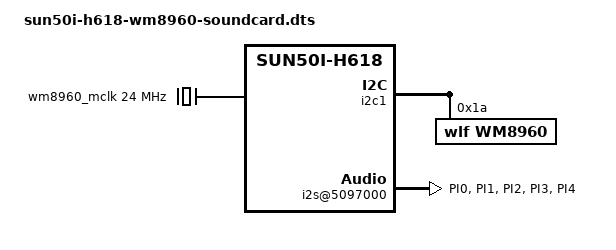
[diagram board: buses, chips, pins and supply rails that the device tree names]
/*
 * Device Tree Overlay for WM8960 Audio Codec (ReSpeaker 2-Mic HAT / Keyestudio)
 * on Orange Pi Zero 2W (Allwinner H618)
 *
 * Copyright (C) 2025
 * License: MIT
 *
 * This overlay enables the WM8960 codec connected via:
 *   - I2C for control (address 0x1a on /dev/i2c-3)
 *   - I2S for audio data via AHUB I2S2
 *
 * IMPORTANT: This overlay requires the base i2c1-pi overlay to be enabled first!
 *   In /boot/armbianEnv.txt, ensure:
 *     overlays=i2c1-pi sun50i-h618-wm8960-soundcard
 *
 * GPIO Pin Mapping (40-pin header):
 *   Pin 3  (PI8)  - I2C SDA 
 *   Pin 5  (PI7)  - I2C SCL
 *   Pin 12 (PI1)  - I2S BCLK
 *   Pin 35 (PI2)  - I2S LRCK
 *   Pin 38 (PI4)  - I2S DIN
 *   Pin 40 (PI3)  - I2S DOUT
 *
 * After enabling i2c1-pi overlay, the I2C appears as /dev/i2c-3
 * The WM8960 should be detected at address 0x1a on that bus.
 */

/dts-v1/;
/plugin/;

/ {
	compatible = "xunlong,orangepi-zero2w", "allwinner,sun50i-h618";

	/* Fragment 0: Add WM8960 codec to I2C1 (which becomes /dev/i2c-3 with i2c1-pi overlay) */
	fragment@0 {
		target = <&i2c1>;
		__overlay__ {
			#address-cells = <1>;
			#size-cells = <0>;
			status = "okay";

			wm8960: wm8960@1a {
				compatible = "wlf,wm8960";
				reg = <0x1a>;
				#sound-dai-cells = <0>;
				wlf,shared-lrclk;
			};
		};
	};

	/* Fragment 1: Define I2S2 pins for audio */
	fragment@1 {
		target = <&pio>;
		__overlay__ {
			i2s2_wm8960_pins: i2s2-wm8960-pins {
				pins = "PI0", "PI1", "PI2", "PI3", "PI4";
				function = "i2s2";
			};
		};
	};

	/* Fragment 2: Enable I2S2 interface with external pinctrl */
	fragment@2 {
		target-path = "/soc/i2s@5097000";
		__overlay__ {
			status = "okay";
			pinctrl-names = "default";
			pinctrl-0 = <&i2s2_wm8960_pins>;
		};
	};

	/* Fragment 3: Create sound card using simple-audio-card */
	fragment@3 {
		target-path = "/";
		__overlay__ {
			wm8960_mclk: wm8960-mclk {
				compatible = "fixed-clock";
				#clock-cells = <0>;
				clock-frequency = <24000000>;
				clock-output-names = "wm8960-mclk";
			};

			sound_wm8960: sound-wm8960 {
				compatible = "simple-audio-card";
				simple-audio-card,name = "wm8960-soundcard";
				simple-audio-card,format = "i2s";
				simple-audio-card,mclk-fs = <256>;
				simple-audio-card,bitclock-master = <&dailink_master>;
				simple-audio-card,frame-master = <&dailink_master>;

				simple-audio-card,widgets =
					"Microphone", "Mic Jack",
					"Line", "Line In",
					"Line", "Line Out",
					"Speaker", "Speaker",
					"Headphone", "Headphone Jack";

				simple-audio-card,routing =
					"Headphone Jack", "HP_L",
					"Headphone Jack", "HP_R",
					"Speaker", "SPK_LP",
					"Speaker", "SPK_LN",
					"Speaker", "SPK_RP",
					"Speaker", "SPK_RN",
					"LINPUT1", "Mic Jack",
					"LINPUT3", "Mic Jack",
					"RINPUT1", "Mic Jack",
					"RINPUT2", "Line In",
					"LINPUT2", "Line In";

				status = "okay";

				simple-audio-card,cpu {
					sound-dai = <&i2s2>;
					dai-tdm-slot-num = <2>;
					dai-tdm-slot-width = <16>;
				};

				dailink_master: simple-audio-card,codec {
					sound-dai = <&wm8960>;
					clocks = <&wm8960_mclk>;
					clock-names = "mclk";
				};
			};
		};
	};
};
